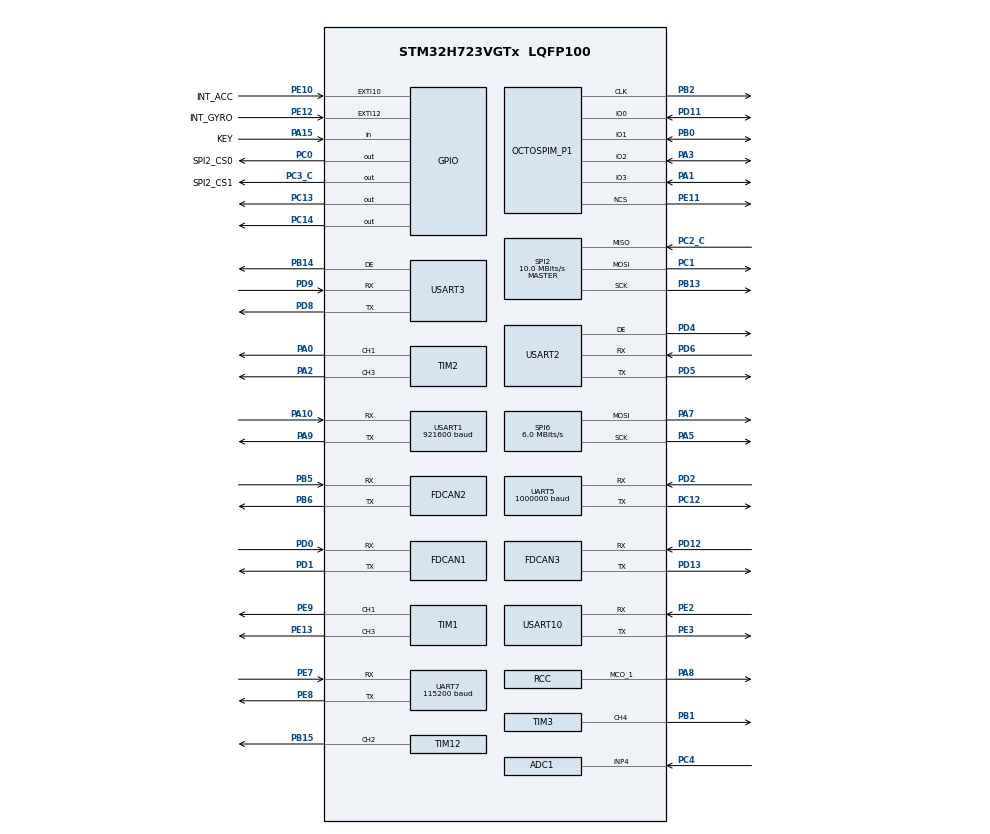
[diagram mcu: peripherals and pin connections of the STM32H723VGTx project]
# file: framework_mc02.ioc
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ADC1.Channel-0\#ChannelRegularConversion=ADC_CHANNEL_4
ADC1.ClockPrescaler=ADC_CLOCK_ASYNC_DIV64
ADC1.ContinuousConvMode=ENABLE
ADC1.ConversionDataManagement=ADC_CONVERSIONDATA_DMA_CIRCULAR
ADC1.EnableAnalogWatchDog1=false
ADC1.NbrOfConversionFlag=1
ADC1.OffsetNumber-0\#ChannelRegularConversion=ADC_OFFSET_NONE
ADC1.OffsetSignedSaturation-0\#ChannelRegularConversion=DISABLE
ADC1.Rank-0\#ChannelRegularConversion=1
ADC1.SamplingTime-0\#ChannelRegularConversion=ADC_SAMPLETIME_32CYCLES_5
ADC1.master=1
Bdma.Request0=SPI6_TX
Bdma.RequestsNb=1
Bdma.SPI6_TX.0.Direction=DMA_MEMORY_TO_PERIPH
Bdma.SPI6_TX.0.EventEnable=DISABLE
Bdma.SPI6_TX.0.Instance=BDMA_Channel0
Bdma.SPI6_TX.0.MemDataAlignment=DMA_MDATAALIGN_BYTE
Bdma.SPI6_TX.0.MemInc=DMA_MINC_ENABLE
Bdma.SPI6_TX.0.Mode=DMA_NORMAL
Bdma.SPI6_TX.0.PeriphDataAlignment=DMA_PDATAALIGN_BYTE
Bdma.SPI6_TX.0.PeriphInc=DMA_PINC_DISABLE
Bdma.SPI6_TX.0.Polarity=HAL_DMAMUX_REQ_GEN_RISING
Bdma.SPI6_TX.0.Priority=DMA_PRIORITY_LOW
Bdma.SPI6_TX.0.RequestNumber=1
Bdma.SPI6_TX.0.SignalID=NONE
Bdma.SPI6_TX.0.SyncEnable=DISABLE
Bdma.SPI6_TX.0.SyncPolarity=HAL_DMAMUX_SYNC_NO_EVENT
Bdma.SPI6_TX.0.SyncRequestNumber=1
Bdma.SPI6_TX.0.SyncSignalID=NONE
CORTEX_M7.AccessPermission-Cortex_Memory_Protection_Unit_Region10_Settings=MPU_REGION_FULL_ACCESS
CORTEX_M7.AccessPermission-Cortex_Memory_Protection_Unit_Region11_Settings=MPU_REGION_FULL_ACCESS
CORTEX_M7.AccessPermission-Cortex_Memory_Protection_Unit_Region12_Settings=MPU_REGION_FULL_ACCESS
CORTEX_M7.AccessPermission-Cortex_Memory_Protection_Unit_Region1_Settings=MPU_REGION_PRIV_RO
CORTEX_M7.AccessPermission-Cortex_Memory_Protection_Unit_Region2_Settings=MPU_REGION_FULL_ACCESS
CORTEX_M7.AccessPermission-Cortex_Memory_Protection_Unit_Region3_Settings=MPU_REGION_FULL_ACCESS
CORTEX_M7.AccessPermission-Cortex_Memory_Protection_Unit_Region4_Settings=MPU_REGION_FULL_ACCESS
CORTEX_M7.AccessPermission-Cortex_Memory_Protection_Unit_Region5_Settings=MPU_REGION_FULL_ACCESS
CORTEX_M7.AccessPermission-Cortex_Memory_Protection_Unit_Region6_Settings=MPU_REGION_FULL_ACCESS
CORTEX_M7.AccessPermission-Cortex_Memory_Protection_Unit_Region7_Settings=MPU_REGION_FULL_ACCESS
CORTEX_M7.AccessPermission-Cortex_Memory_Protection_Unit_Region8_Settings=MPU_REGION_FULL_ACCESS
CORTEX_M7.AccessPermission-Cortex_Memory_Protection_Unit_Region9_Settings=MPU_REGION_FULL_ACCESS
CORTEX_M7.BaseAddress-Cortex_Memory_Protection_Unit_Region10_Settings=0x48020000
CORTEX_M7.BaseAddress-Cortex_Memory_Protection_Unit_Region11_Settings=0x40020000
CORTEX_M7.BaseAddress-Cortex_Memory_Protection_Unit_Region12_Settings=0x40010000
CORTEX_M7.BaseAddress-Cortex_Memory_Protection_Unit_Region2_Settings=0x20000000
CORTEX_M7.BaseAddress-Cortex_Memory_Protection_Unit_Region3_Settings=0x24000000
CORTEX_M7.BaseAddress-Cortex_Memory_Protection_Unit_Region4_Settings=0x30000000
CORTEX_M7.BaseAddress-Cortex_Memory_Protection_Unit_Region5_Settings=0x38000000
CORTEX_M7.BaseAddress-Cortex_Memory_Protection_Unit_Region6_Settings=0x38800000
CORTEX_M7.BaseAddress-Cortex_Memory_Protection_Unit_Region7_Settings=0x58000000
CORTEX_M7.BaseAddress-Cortex_Memory_Protection_Unit_Region8_Settings=0x51000000
CORTEX_M7.BaseAddress-Cortex_Memory_Protection_Unit_Region9_Settings=0x50000000
CORTEX_M7.CPU_DCache=Enabled
CORTEX_M7.CPU_ICache=Enabled
CORTEX_M7.DisableExec-Cortex_Memory_Protection_Unit_Region0_Settings=MPU_INSTRUCTION_ACCESS_DISABLE
CORTEX_M7.Enable-Cortex_Memory_Protection_Unit_Region0_Settings=MPU_REGION_ENABLE
CORTEX_M7.Enable-Cortex_Memory_Protection_Unit_Region10_Settings=MPU_REGION_ENABLE
CORTEX_M7.Enable-Cortex_Memory_Protection_Unit_Region11_Settings=MPU_REGION_ENABLE
CORTEX_M7.Enable-Cortex_Memory_Protection_Unit_Region12_Settings=MPU_REGION_ENABLE
CORTEX_M7.Enable-Cortex_Memory_Protection_Unit_Region1_Settings=MPU_REGION_ENABLE
CORTEX_M7.Enable-Cortex_Memory_Protection_Unit_Region2_Settings=MPU_REGION_ENABLE
CORTEX_M7.Enable-Cortex_Memory_Protection_Unit_Region3_Settings=MPU_REGION_ENABLE
CORTEX_M7.Enable-Cortex_Memory_Protection_Unit_Region4_Settings=MPU_REGION_ENABLE
CORTEX_M7.Enable-Cortex_Memory_Protection_Unit_Region5_Settings=MPU_REGION_ENABLE
CORTEX_M7.Enable-Cortex_Memory_Protection_Unit_Region6_Settings=MPU_REGION_ENABLE
CORTEX_M7.Enable-Cortex_Memory_Protection_Unit_Region7_Settings=MPU_REGION_ENABLE
CORTEX_M7.Enable-Cortex_Memory_Protection_Unit_Region8_Settings=MPU_REGION_ENABLE
CORTEX_M7.Enable-Cortex_Memory_Protection_Unit_Region9_Settings=MPU_REGION_ENABLE
CORTEX_M7.IsBufferable-Cortex_Memory_Protection_Unit_Region1_Settings=MPU_ACCESS_NOT_BUFFERABLE
CORTEX_M7.IsBufferable-Cortex_Memory_Protection_Unit_Region2_Settings=MPU_ACCESS_BUFFERABLE
CORTEX_M7.IsCacheable-Cortex_Memory_Protection_Unit_Region1_Settings=MPU_ACCESS_CACHEABLE
CORTEX_M7.IsCacheable-Cortex_Memory_Protection_Unit_Region2_Settings=MPU_ACCESS_CACHEABLE
CORTEX_M7.IsCacheable-Cortex_Memory_Protection_Unit_Region3_Settings=MPU_ACCESS_CACHEABLE
CORTEX_M7.MPU_Control=MPU_PRIVILEGED_DEFAULT
CORTEX_M7.Size-Cortex_Memory_Protection_Unit_Region10_Settings=MPU_REGION_SIZE_16KB
CORTEX_M7.Size-Cortex_Memory_Protection_Unit_Region11_Settings=MPU_REGION_SIZE_1MB
CORTEX_M7.Size-Cortex_Memory_Protection_Unit_Region12_Settings=MPU_REGION_SIZE_32KB
CORTEX_M7.Size-Cortex_Memory_Protection_Unit_Region1_Settings=MPU_REGION_SIZE_64KB
CORTEX_M7.Size-Cortex_Memory_Protection_Unit_Region2_Settings=MPU_REGION_SIZE_128KB
CORTEX_M7.Size-Cortex_Memory_Protection_Unit_Region3_Settings=MPU_REGION_SIZE_512KB
CORTEX_M7.Size-Cortex_Memory_Protection_Unit_Region4_Settings=MPU_REGION_SIZE_32KB
CORTEX_M7.Size-Cortex_Memory_Protection_Unit_Region5_Settings=MPU_REGION_SIZE_16KB
CORTEX_M7.Size-Cortex_Memory_Protection_Unit_Region6_Settings=MPU_REGION_SIZE_4KB
CORTEX_M7.Size-Cortex_Memory_Protection_Unit_Region7_Settings=MPU_REGION_SIZE_256KB
CORTEX_M7.Size-Cortex_Memory_Protection_Unit_Region8_Settings=MPU_REGION_SIZE_64KB
CORTEX_M7.Size-Cortex_Memory_Protection_Unit_Region9_Settings=MPU_REGION_SIZE_16KB
CORTEX_M7.SubRegionDisable-Cortex_Memory_Protection_Unit_Region10_Settings=0x03
CORTEX_M7.SubRegionDisable-Cortex_Memory_Protection_Unit_Region11_Settings=0x07
CORTEX_M7.SubRegionDisable-Cortex_Memory_Protection_Unit_Region3_Settings=0x07
CORTEX_M7.SubRegionDisable-Cortex_Memory_Protection_Unit_Region7_Settings=0x07
CORTEX_M7.SubRegionDisable-Cortex_Memory_Protection_Unit_Region8_Settings=0x07
CORTEX_M7.TypeExtField-Cortex_Memory_Protection_Unit_Region10_Settings=MPU_TEX_LEVEL1
CORTEX_M7.TypeExtField-Cortex_Memory_Protection_Unit_Region11_Settings=MPU_TEX_LEVEL1
CORTEX_M7.TypeExtField-Cortex_Memory_Protection_Unit_Region12_Settings=MPU_TEX_LEVEL1
CORTEX_M7.TypeExtField-Cortex_Memory_Protection_Unit_Region7_Settings=MPU_TEX_LEVEL1
CORTEX_M7.TypeExtField-Cortex_Memory_Protection_Unit_Region8_Settings=MPU_TEX_LEVEL1
CORTEX_M7.TypeExtField-Cortex_Memory_Protection_Unit_Region9_Settings=MPU_TEX_LEVEL1
CORTEX_M7.default_mode_Activation=0
Dma.ADC1.0.Direction=DMA_PERIPH_TO_MEMORY
Dma.ADC1.0.EventEnable=DISABLE
Dma.ADC1.0.FIFOMode=DMA_FIFOMODE_DISABLE
Dma.ADC1.0.Instance=DMA1_Stream0
Dma.ADC1.0.MemDataAlignment=DMA_MDATAALIGN_HALFWORD
Dma.ADC1.0.MemInc=DMA_MINC_ENABLE
Dma.ADC1.0.Mode=DMA_NORMAL
Dma.ADC1.0.PeriphDataAlignment=DMA_PDATAALIGN_HALFWORD
Dma.ADC1.0.PeriphInc=DMA_PINC_DISABLE
Dma.ADC1.0.Polarity=HAL_DMAMUX_REQ_GEN_RISING
Dma.ADC1.0.Priority=DMA_PRIORITY_LOW
Dma.ADC1.0.RequestNumber=1
Dma.ADC1.0.SignalID=NONE
Dma.ADC1.0.SyncEnable=DISABLE
Dma.ADC1.0.SyncPolarity=HAL_DMAMUX_SYNC_NO_EVENT
Dma.ADC1.0.SyncRequestNumber=1
Dma.ADC1.0.SyncSignalID=NONE
Dma.Request0=ADC1
Dma.Request1=USART1_RX
Dma.Request10=UART7_RX
Dma.Request11=UART7_TX
Dma.Request12=SPI2_TX
Dma.Request13=SPI2_RX
Dma.Request2=USART1_TX
Dma.Request3=USART2_RX
Dma.Request4=USART2_TX
Dma.Request5=USART3_RX
Dma.Request6=USART3_TX
Dma.Request7=USART10_RX
Dma.Request8=USART10_TX
Dma.Request9=UART5_RX
Dma.SPI2_RX.13.Direction=DMA_PERIPH_TO_MEMORY
Dma.SPI2_RX.13.EventEnable=DISABLE
Dma.SPI2_RX.13.FIFOMode=DMA_FIFOMODE_DISABLE
Dma.SPI2_RX.13.Instance=DMA2_Stream5
Dma.SPI2_RX.13.MemDataAlignment=DMA_MDATAALIGN_BYTE
Dma.SPI2_RX.13.MemInc=DMA_MINC_ENABLE
Dma.SPI2_RX.13.Mode=DMA_NORMAL
Dma.SPI2_RX.13.PeriphDataAlignment=DMA_PDATAALIGN_BYTE
Dma.SPI2_RX.13.PeriphInc=DMA_PINC_DISABLE
Dma.SPI2_RX.13.Polarity=HAL_DMAMUX_REQ_GEN_RISING
Dma.SPI2_RX.13.Priority=DMA_PRIORITY_LOW
Dma.SPI2_RX.13.RequestNumber=1
Dma.SPI2_RX.13.SignalID=NONE
Dma.SPI2_RX.13.SyncEnable=DISABLE
Dma.SPI2_RX.13.SyncPolarity=HAL_DMAMUX_SYNC_NO_EVENT
Dma.SPI2_RX.13.SyncRequestNumber=1
Dma.SPI2_RX.13.SyncSignalID=NONE
Dma.SPI2_TX.12.Direction=DMA_MEMORY_TO_PERIPH
Dma.SPI2_TX.12.EventEnable=DISABLE
Dma.SPI2_TX.12.FIFOMode=DMA_FIFOMODE_DISABLE
Dma.SPI2_TX.12.Instance=DMA2_Stream4
Dma.SPI2_TX.12.MemDataAlignment=DMA_MDATAALIGN_BYTE
Dma.SPI2_TX.12.MemInc=DMA_MINC_ENABLE
Dma.SPI2_TX.12.Mode=DMA_NORMAL
Dma.SPI2_TX.12.PeriphDataAlignment=DMA_PDATAALIGN_BYTE
Dma.SPI2_TX.12.PeriphInc=DMA_PINC_DISABLE
Dma.SPI2_TX.12.Polarity=HAL_DMAMUX_REQ_GEN_RISING
Dma.SPI2_TX.12.Priority=DMA_PRIORITY_LOW
Dma.SPI2_TX.12.RequestNumber=1
Dma.SPI2_TX.12.SignalID=NONE
Dma.SPI2_TX.12.SyncEnable=DISABLE
Dma.SPI2_TX.12.SyncPolarity=HAL_DMAMUX_SYNC_NO_EVENT
Dma.SPI2_TX.12.SyncRequestNumber=1
Dma.SPI2_TX.12.SyncSignalID=NONE
Dma.UART5_RX.9.Direction=DMA_PERIPH_TO_MEMORY
Dma.UART5_RX.9.EventEnable=DISABLE
Dma.UART5_RX.9.FIFOMode=DMA_FIFOMODE_DISABLE
Dma.UART5_RX.9.Instance=DMA2_Stream1
Dma.UART5_RX.9.MemDataAlignment=DMA_MDATAALIGN_BYTE
Dma.UART5_RX.9.MemInc=DMA_MINC_ENABLE
Dma.UART5_RX.9.Mode=DMA_NORMAL
Dma.UART5_RX.9.PeriphDataAlignment=DMA_PDATAALIGN_BYTE
Dma.UART5_RX.9.PeriphInc=DMA_PINC_DISABLE
Dma.UART5_RX.9.Polarity=HAL_DMAMUX_REQ_GEN_RISING
Dma.UART5_RX.9.Priority=DMA_PRIORITY_LOW
Dma.UART5_RX.9.RequestNumber=1
Dma.UART5_RX.9.SignalID=NONE
Dma.UART5_RX.9.SyncEnable=DISABLE
Dma.UART5_RX.9.SyncPolarity=HAL_DMAMUX_SYNC_NO_EVENT
Dma.UART5_RX.9.SyncRequestNumber=1
Dma.UART5_RX.9.SyncSignalID=NONE
Dma.UART7_RX.10.Direction=DMA_PERIPH_TO_MEMORY
Dma.UART7_RX.10.EventEnable=DISABLE
Dma.UART7_RX.10.FIFOMode=DMA_FIFOMODE_DISABLE
Dma.UART7_RX.10.Instance=DMA2_Stream2
Dma.UART7_RX.10.MemDataAlignment=DMA_MDATAALIGN_BYTE
Dma.UART7_RX.10.MemInc=DMA_MINC_ENABLE
Dma.UART7_RX.10.Mode=DMA_NORMAL
Dma.UART7_RX.10.PeriphDataAlignment=DMA_PDATAALIGN_BYTE
Dma.UART7_RX.10.PeriphInc=DMA_PINC_DISABLE
Dma.UART7_RX.10.Polarity=HAL_DMAMUX_REQ_GEN_RISING
Dma.UART7_RX.10.Priority=DMA_PRIORITY_LOW
Dma.UART7_RX.10.RequestNumber=1
Dma.UART7_RX.10.SignalID=NONE
Dma.UART7_RX.10.SyncEnable=DISABLE
Dma.UART7_RX.10.SyncPolarity=HAL_DMAMUX_SYNC_NO_EVENT
Dma.UART7_RX.10.SyncRequestNumber=1
Dma.UART7_RX.10.SyncSignalID=NONE
Dma.UART7_TX.11.Direction=DMA_MEMORY_TO_PERIPH
Dma.UART7_TX.11.EventEnable=DISABLE
Dma.UART7_TX.11.FIFOMode=DMA_FIFOMODE_DISABLE
Dma.UART7_TX.11.Instance=DMA2_Stream3
Dma.UART7_TX.11.MemDataAlignment=DMA_MDATAALIGN_BYTE
Dma.UART7_TX.11.MemInc=DMA_MINC_ENABLE
Dma.UART7_TX.11.Mode=DMA_NORMAL
Dma.UART7_TX.11.PeriphDataAlignment=DMA_PDATAALIGN_BYTE
Dma.UART7_TX.11.PeriphInc=DMA_PINC_DISABLE
Dma.UART7_TX.11.Polarity=HAL_DMAMUX_REQ_GEN_RISING
Dma.UART7_TX.11.Priority=DMA_PRIORITY_LOW
Dma.UART7_TX.11.RequestNumber=1
Dma.UART7_TX.11.SignalID=NONE
Dma.UART7_TX.11.SyncEnable=DISABLE
Dma.UART7_TX.11.SyncPolarity=HAL_DMAMUX_SYNC_NO_EVENT
Dma.UART7_TX.11.SyncRequestNumber=1
Dma.UART7_TX.11.SyncSignalID=NONE
Dma.USART10_RX.7.Direction=DMA_PERIPH_TO_MEMORY
Dma.USART10_RX.7.EventEnable=DISABLE
Dma.USART10_RX.7.FIFOMode=DMA_FIFOMODE_DISABLE
Dma.USART10_RX.7.Instance=DMA1_Stream7
Dma.USART10_RX.7.MemDataAlignment=DMA_MDATAALIGN_BYTE
Dma.USART10_RX.7.MemInc=DMA_MINC_ENABLE
Dma.USART10_RX.7.Mode=DMA_NORMAL
Dma.USART10_RX.7.PeriphDataAlignment=DMA_PDATAALIGN_BYTE
Dma.USART10_RX.7.PeriphInc=DMA_PINC_DISABLE
Dma.USART10_RX.7.Polarity=HAL_DMAMUX_REQ_GEN_RISING
Dma.USART10_RX.7.Priority=DMA_PRIORITY_LOW
Dma.USART10_RX.7.RequestNumber=1
Dma.USART10_RX.7.SignalID=NONE
Dma.USART10_RX.7.SyncEnable=DISABLE
Dma.USART10_RX.7.SyncPolarity=HAL_DMAMUX_SYNC_NO_EVENT
Dma.USART10_RX.7.SyncRequestNumber=1
Dma.USART10_RX.7.SyncSignalID=NONE
Dma.USART10_TX.8.Direction=DMA_MEMORY_TO_PERIPH
Dma.USART10_TX.8.EventEnable=DISABLE
Dma.USART10_TX.8.FIFOMode=DMA_FIFOMODE_DISABLE
Dma.USART10_TX.8.Instance=DMA2_Stream0
Dma.USART10_TX.8.MemDataAlignment=DMA_MDATAALIGN_BYTE
Dma.USART10_TX.8.MemInc=DMA_MINC_ENABLE
Dma.USART10_TX.8.Mode=DMA_NORMAL
Dma.USART10_TX.8.PeriphDataAlignment=DMA_PDATAALIGN_BYTE
Dma.USART10_TX.8.PeriphInc=DMA_PINC_DISABLE
Dma.USART10_TX.8.Polarity=HAL_DMAMUX_REQ_GEN_RISING
Dma.USART10_TX.8.Priority=DMA_PRIORITY_LOW
Dma.USART10_TX.8.RequestNumber=1
Dma.USART10_TX.8.SignalID=NONE
Dma.USART10_TX.8.SyncEnable=DISABLE
Dma.USART10_TX.8.SyncPolarity=HAL_DMAMUX_SYNC_NO_EVENT
Dma.USART10_TX.8.SyncRequestNumber=1
Dma.USART10_TX.8.SyncSignalID=NONE
Dma.USART1_RX.1.Direction=DMA_PERIPH_TO_MEMORY
Dma.USART1_RX.1.EventEnable=DISABLE
Dma.USART1_RX.1.FIFOMode=DMA_FIFOMODE_DISABLE
Dma.USART1_RX.1.Instance=DMA1_Stream1
Dma.USART1_RX.1.MemDataAlignment=DMA_MDATAALIGN_BYTE
Dma.USART1_RX.1.MemInc=DMA_MINC_ENABLE
Dma.USART1_RX.1.Mode=DMA_NORMAL
Dma.USART1_RX.1.PeriphDataAlignment=DMA_PDATAALIGN_BYTE
Dma.USART1_RX.1.PeriphInc=DMA_PINC_DISABLE
Dma.USART1_RX.1.Polarity=HAL_DMAMUX_REQ_GEN_RISING
Dma.USART1_RX.1.Priority=DMA_PRIORITY_LOW
Dma.USART1_RX.1.RequestNumber=1
Dma.USART1_RX.1.SignalID=NONE
Dma.USART1_RX.1.SyncEnable=DISABLE
Dma.USART1_RX.1.SyncPolarity=HAL_DMAMUX_SYNC_NO_EVENT
Dma.USART1_RX.1.SyncRequestNumber=1
Dma.USART1_RX.1.SyncSignalID=NONE
Dma.USART1_TX.2.Direction=DMA_MEMORY_TO_PERIPH
Dma.USART1_TX.2.EventEnable=DISABLE
Dma.USART1_TX.2.FIFOMode=DMA_FIFOMODE_DISABLE
Dma.USART1_TX.2.Instance=DMA1_Stream2
Dma.USART1_TX.2.MemDataAlignment=DMA_MDATAALIGN_BYTE
Dma.USART1_TX.2.MemInc=DMA_MINC_ENABLE
Dma.USART1_TX.2.Mode=DMA_NORMAL
Dma.USART1_TX.2.PeriphDataAlignment=DMA_PDATAALIGN_BYTE
Dma.USART1_TX.2.PeriphInc=DMA_PINC_DISABLE
Dma.USART1_TX.2.Polarity=HAL_DMAMUX_REQ_GEN_RISING
Dma.USART1_TX.2.Priority=DMA_PRIORITY_LOW
Dma.USART1_TX.2.RequestNumber=1
Dma.USART1_TX.2.SignalID=NONE
Dma.USART1_TX.2.SyncEnable=DISABLE
Dma.USART1_TX.2.SyncPolarity=HAL_DMAMUX_SYNC_NO_EVENT
Dma.USART1_TX.2.SyncRequestNumber=1
Dma.USART1_TX.2.SyncSignalID=NONE
Dma.USART2_RX.3.Direction=DMA_PERIPH_TO_MEMORY
Dma.USART2_RX.3.EventEnable=DISABLE
Dma.USART2_RX.3.FIFOMode=DMA_FIFOMODE_DISABLE
Dma.USART2_RX.3.Instance=DMA1_Stream3
Dma.USART2_RX.3.MemDataAlignment=DMA_MDATAALIGN_BYTE
Dma.USART2_RX.3.MemInc=DMA_MINC_ENABLE
Dma.USART2_RX.3.Mode=DMA_NORMAL
Dma.USART2_RX.3.PeriphDataAlignment=DMA_PDATAALIGN_BYTE
Dma.USART2_RX.3.PeriphInc=DMA_PINC_DISABLE
Dma.USART2_RX.3.Polarity=HAL_DMAMUX_REQ_GEN_RISING
Dma.USART2_RX.3.Priority=DMA_PRIORITY_LOW
Dma.USART2_RX.3.RequestNumber=1
Dma.USART2_RX.3.SignalID=NONE
Dma.USART2_RX.3.SyncEnable=DISABLE
Dma.USART2_RX.3.SyncPolarity=HAL_DMAMUX_SYNC_NO_EVENT
Dma.USART2_RX.3.SyncRequestNumber=1
Dma.USART2_RX.3.SyncSignalID=NONE
Dma.USART2_TX.4.Direction=DMA_MEMORY_TO_PERIPH
Dma.USART2_TX.4.EventEnable=DISABLE
Dma.USART2_TX.4.FIFOMode=DMA_FIFOMODE_DISABLE
Dma.USART2_TX.4.Instance=DMA1_Stream4
Dma.USART2_TX.4.MemDataAlignment=DMA_MDATAALIGN_BYTE
Dma.USART2_TX.4.MemInc=DMA_MINC_ENABLE
Dma.USART2_TX.4.Mode=DMA_NORMAL
Dma.USART2_TX.4.PeriphDataAlignment=DMA_PDATAALIGN_BYTE
Dma.USART2_TX.4.PeriphInc=DMA_PINC_DISABLE
Dma.USART2_TX.4.Polarity=HAL_DMAMUX_REQ_GEN_RISING
Dma.USART2_TX.4.Priority=DMA_PRIORITY_LOW
Dma.USART2_TX.4.RequestNumber=1
Dma.USART2_TX.4.SignalID=NONE
Dma.USART2_TX.4.SyncEnable=DISABLE
Dma.USART2_TX.4.SyncPolarity=HAL_DMAMUX_SYNC_NO_EVENT
Dma.USART2_TX.4.SyncRequestNumber=1
Dma.USART2_TX.4.SyncSignalID=NONE
Dma.USART3_RX.5.Direction=DMA_PERIPH_TO_MEMORY
Dma.USART3_RX.5.EventEnable=DISABLE
Dma.USART3_RX.5.FIFOMode=DMA_FIFOMODE_DISABLE
Dma.USART3_RX.5.Instance=DMA1_Stream5
Dma.USART3_RX.5.MemDataAlignment=DMA_MDATAALIGN_BYTE
Dma.USART3_RX.5.MemInc=DMA_MINC_ENABLE
Dma.USART3_RX.5.Mode=DMA_NORMAL
Dma.USART3_RX.5.PeriphDataAlignment=DMA_PDATAALIGN_BYTE
Dma.USART3_RX.5.PeriphInc=DMA_PINC_DISABLE
Dma.USART3_RX.5.Polarity=HAL_DMAMUX_REQ_GEN_RISING
Dma.USART3_RX.5.Priority=DMA_PRIORITY_LOW
Dma.USART3_RX.5.RequestNumber=1
Dma.USART3_RX.5.SignalID=NONE
Dma.USART3_RX.5.SyncEnable=DISABLE
Dma.USART3_RX.5.SyncPolarity=HAL_DMAMUX_SYNC_NO_EVENT
Dma.USART3_RX.5.SyncRequestNumber=1
Dma.USART3_RX.5.SyncSignalID=NONE
Dma.USART3_TX.6.Direction=DMA_MEMORY_TO_PERIPH
Dma.USART3_TX.6.EventEnable=DISABLE
Dma.USART3_TX.6.FIFOMode=DMA_FIFOMODE_DISABLE
Dma.USART3_TX.6.Instance=DMA1_Stream6
Dma.USART3_TX.6.MemDataAlignment=DMA_MDATAALIGN_BYTE
Dma.USART3_TX.6.MemInc=DMA_MINC_ENABLE
Dma.USART3_TX.6.Mode=DMA_NORMAL
Dma.USART3_TX.6.PeriphDataAlignment=DMA_PDATAALIGN_BYTE
Dma.USART3_TX.6.PeriphInc=DMA_PINC_DISABLE
Dma.USART3_TX.6.Polarity=HAL_DMAMUX_REQ_GEN_RISING
Dma.USART3_TX.6.Priority=DMA_PRIORITY_LOW
Dma.USART3_TX.6.RequestNumber=1
Dma.USART3_TX.6.SignalID=NONE
Dma.USART3_TX.6.SyncEnable=DISABLE
Dma.USART3_TX.6.SyncPolarity=HAL_DMAMUX_SYNC_NO_EVENT
Dma.USART3_TX.6.SyncRequestNumber=1
Dma.USART3_TX.6.SyncSignalID=NONE
FDCAN1.CalculateBaudRateNominal=1000000
FDCAN1.CalculateTimeBitNominal=1000
FDCAN1.CalculateTimeQuantumNominal=25.0
FDCAN1.DataPrescaler=1
FDCAN1.DataSyncJumpWidth=2
FDCAN1.DataTimeSeg1=10
FDCAN1.DataTimeSeg2=5
FDCAN1.ExtFiltersNbr=1
FDCAN1.FrameFormat=FDCAN_FRAME_FD_BRS
FDCAN1.NominalPrescaler=2
FDCAN1.NominalSyncJumpWidth=2
FDCAN1.NominalTimeSeg1=29
FDCAN1.NominalTimeSeg2=10
FDCAN1.ProtocolException=ENABLE
FDCAN1.RxFifo0ElmtSize=FDCAN_DATA_BYTES_64
FDCAN1.RxFifo0ElmtsNbr=8
FDCAN1.RxFifo1ElmtsNbr=0
FDCAN1.StdFiltersNbr=1
FDCAN1.TxElmtSize=FDCAN_DATA_BYTES_64
FDCAN1.TxFifoQueueElmtsNbr=32
FDCAN2.CalculateBaudRateNominal=1000000
FDCAN2.CalculateTimeBitNominal=1000
FDCAN2.CalculateTimeQuantumNominal=25.0
FDCAN2.DataPrescaler=1
FDCAN2.DataSyncJumpWidth=2
FDCAN2.DataTimeSeg1=10
FDCAN2.DataTimeSeg2=5
FDCAN2.ExtFiltersNbr=1
FDCAN2.FrameFormat=FDCAN_FRAME_FD_BRS
FDCAN2.MessageRAMOffset=(768 - 1)
FDCAN2.NominalPrescaler=2
FDCAN2.NominalSyncJumpWidth=2
FDCAN2.NominalTimeSeg1=29
FDCAN2.NominalTimeSeg2=10
FDCAN2.ProtocolException=ENABLE
FDCAN2.RxFifo0ElmtSize=FDCAN_DATA_BYTES_8
FDCAN2.RxFifo0ElmtsNbr=0
FDCAN2.RxFifo1ElmtSize=FDCAN_DATA_BYTES_64
FDCAN2.RxFifo1ElmtsNbr=8
FDCAN2.StdFiltersNbr=1
FDCAN2.TxElmtSize=FDCAN_DATA_BYTES_64
FDCAN2.TxFifoQueueElmtsNbr=32
FDCAN3.CalculateBaudRateNominal=1000000
FDCAN3.CalculateTimeBitNominal=1000
FDCAN3.CalculateTimeQuantumNominal=25.0
FDCAN3.DataPrescaler=1
FDCAN3.DataSyncJumpWidth=2
FDCAN3.DataTimeSeg1=10
FDCAN3.DataTimeSeg2=5
FDCAN3.ExtFiltersNbr=1
FDCAN3.FrameFormat=FDCAN_FRAME_FD_BRS
FDCAN3.MessageRAMOffset=(1536 - 1)
FDCAN3.NominalPrescaler=2
FDCAN3.NominalSyncJumpWidth=2
FDCAN3.NominalTimeSeg1=29
FDCAN3.NominalTimeSeg2=10
FDCAN3.ProtocolException=ENABLE
FDCAN3.RxFifo1ElmtSize=FDCAN_DATA_BYTES_64
FDCAN3.RxFifo1ElmtsNbr=8
FDCAN3.StdFiltersNbr=1
FDCAN3.TxElmtSize=FDCAN_DATA_BYTES_64
FDCAN3.TxFifoQueueElmtsNbr=32
FREERTOS.INCLUDE_vTaskCleanUpResources=1
FREERTOS.INCLUDE_vTaskDelayUntil=0
FREERTOS.INCLUDE_xTaskGetCurrentTaskHandle=1
FREERTOS.Tasks01=defaultTask,0,1024,StartDefaultTask,As weak,NULL,Dynamic,NULL,NULL
FREERTOS.configCHECK_FOR_STACK_OVERFLOW=2
FREERTOS.configENABLE_BACKWARD_COMPATIBILITY=0
FREERTOS.configENABLE_FPU=1
FREERTOS.configGENERATE_RUN_TIME_STATS=1
FREERTOS.configRECORD_STACK_HIGH_ADDRESS=1
FREERTOS.configTOTAL_HEAP_SIZE=0x8000
FREERTOS.configUSE_COUNTING_SEMAPHORES=1
FREERTOS.configUSE_NEWLIB_REENTRANT=1
FREERTOS.configUSE_POSIX_ERRNO=1
FREERTOS.configUSE_TRACE_FACILITY=1
IWDG1.Prescaler=IWDG_PRESCALER_64
Mcu.Family=STM32H7
Mcu.Name=STM32H723VGTx
Mcu.Package=LQFP100
Mdma.MDMA_Channel0.OCTOSPI1_FIFO_TH.0.BlockCount=0
Mdma.MDMA_Channel0.OCTOSPI1_FIFO_TH.0.BlockDataLength=0
Mdma.MDMA_Channel0.OCTOSPI1_FIFO_TH.0.BufferTransferLength=1
Mdma.MDMA_Channel0.OCTOSPI1_FIFO_TH.0.CircularMode=MDMA_LINEAR_LIST
Mdma.MDMA_Channel0.OCTOSPI1_FIFO_TH.0.DataAlignment=MDMA_DATAALIGN_PACKENABLE
Mdma.MDMA_Channel0.OCTOSPI1_FIFO_TH.0.DestBlockAddressOffset=0
Mdma.MDMA_Channel0.OCTOSPI1_FIFO_TH.0.DestBurst=MDMA_DEST_BURST_SINGLE
Mdma.MDMA_Channel0.OCTOSPI1_FIFO_TH.0.DestDataSize=MDMA_DEST_DATASIZE_BYTE
Mdma.MDMA_Channel0.OCTOSPI1_FIFO_TH.0.DestinationInc=MDMA_DEST_INC_BYTE
Mdma.MDMA_Channel0.OCTOSPI1_FIFO_TH.0.DstAddress=0
Mdma.MDMA_Channel0.OCTOSPI1_FIFO_TH.0.Endianness=MDMA_LITTLE_ENDIANNESS_PRESERVE
Mdma.MDMA_Channel0.OCTOSPI1_FIFO_TH.0.Instance=MDMA_Channel0
Mdma.MDMA_Channel0.OCTOSPI1_FIFO_TH.0.MaskAddress=0
Mdma.MDMA_Channel0.OCTOSPI1_FIFO_TH.0.MaskData=0
Mdma.MDMA_Channel0.OCTOSPI1_FIFO_TH.0.Priority=MDMA_PRIORITY_LOW
Mdma.MDMA_Channel0.OCTOSPI1_FIFO_TH.0.Rank=First
Mdma.MDMA_Channel0.OCTOSPI1_FIFO_TH.0.SourceBlockAddressOffset=0
Mdma.MDMA_Channel0.OCTOSPI1_FIFO_TH.0.SourceBurst=MDMA_SOURCE_BURST_SINGLE
Mdma.MDMA_Channel0.OCTOSPI1_FIFO_TH.0.SourceDataSize=MDMA_SRC_DATASIZE_BYTE
Mdma.MDMA_Channel0.OCTOSPI1_FIFO_TH.0.SourceInc=MDMA_SRC_INC_BYTE
Mdma.MDMA_Channel0.OCTOSPI1_FIFO_TH.0.SrcAddress=0
Mdma.MDMA_Channel0.OCTOSPI1_FIFO_TH.0.TransferTriggerMode=MDMA_BUFFER_TRANSFER
Mdma.MDMA_Channel0.Request0=OCTOSPI1_FIFO_TH
Mdma.MDMA_Channel0.RequestsNb=1
Mdma.RequestSet0=MDMA_Channel0
Mdma.RequestSetsNb=1
NVIC.ADC_IRQn=true\:5\:0\:false\:false\:true\:true\:true\:true\:true
NVIC.BDMA_Channel0_IRQn=true\:5\:0\:false\:false\:true\:true\:false\:true\:true
NVIC.DMA1_Stream0_IRQn=true\:5\:0\:false\:false\:true\:true\:false\:true\:true
NVIC.DMA1_Stream1_IRQn=true\:5\:0\:false\:false\:true\:true\:false\:true\:true
NVIC.DMA1_Stream2_IRQn=true\:5\:0\:false\:false\:true\:true\:false\:true\:true
NVIC.DMA1_Stream3_IRQn=true\:5\:0\:false\:false\:true\:true\:false\:true\:true
NVIC.DMA1_Stream4_IRQn=true\:5\:0\:false\:false\:true\:true\:false\:true\:true
NVIC.DMA1_Stream5_IRQn=true\:5\:0\:false\:false\:true\:true\:false\:true\:true
NVIC.DMA1_Stream6_IRQn=true\:5\:0\:false\:false\:true\:true\:false\:true\:true
NVIC.DMA1_Stream7_IRQn=true\:5\:0\:false\:false\:true\:true\:false\:true\:true
NVIC.DMA2_Stream0_IRQn=true\:5\:0\:false\:false\:true\:true\:false\:true\:true
NVIC.DMA2_Stream1_IRQn=true\:5\:0\:false\:false\:true\:true\:false\:true\:true
NVIC.DMA2_Stream2_IRQn=true\:5\:0\:false\:false\:true\:true\:false\:true\:true
NVIC.DMA2_Stream3_IRQn=true\:5\:0\:false\:false\:true\:true\:false\:true\:true
NVIC.DMA2_Stream4_IRQn=true\:5\:0\:false\:false\:true\:true\:false\:true\:true
NVIC.DMA2_Stream5_IRQn=true\:5\:0\:false\:false\:true\:true\:false\:true\:true
NVIC.EXTI15_10_IRQn=true\:5\:0\:false\:false\:true\:true\:true\:true\:true
NVIC.FDCAN1_IT0_IRQn=true\:5\:0\:false\:false\:true\:true\:true\:true\:true
NVIC.FDCAN1_IT1_IRQn=true\:5\:0\:false\:false\:true\:true\:true\:true\:true
NVIC.FDCAN2_IT0_IRQn=true\:5\:0\:false\:false\:true\:true\:true\:true\:true
NVIC.FDCAN2_IT1_IRQn=true\:5\:0\:false\:false\:true\:true\:true\:true\:true
NVIC.FDCAN3_IT0_IRQn=true\:5\:0\:false\:false\:true\:true\:true\:true\:true
NVIC.FDCAN3_IT1_IRQn=true\:5\:0\:false\:false\:true\:true\:true\:true\:true
NVIC.MDMA_IRQn=true\:5\:0\:false\:false\:true\:true\:false\:true\:true
NVIC.OCTOSPI1_IRQn=true\:5\:0\:false\:false\:true\:true\:true\:true\:true
NVIC.PriorityGroup=NVIC_PRIORITYGROUP_4
NVIC.SPI2_IRQn=true\:5\:0\:false\:false\:true\:true\:false\:true\:true
NVIC.SPI6_IRQn=true\:5\:0\:false\:false\:true\:true\:false\:true\:true
NVIC.TIM17_IRQn=true\:15\:0\:false\:false\:true\:false\:false\:true\:true
NVIC.TIM5_IRQn=true\:5\:0\:false\:false\:true\:true\:true\:true\:true
NVIC.TimeBase=TIM17_IRQn
NVIC.TimeBaseIP=TIM17
NVIC.UART5_IRQn=true\:5\:0\:false\:false\:true\:true\:true\:true\:true
NVIC.UART7_IRQn=true\:5\:0\:false\:false\:true\:true\:true\:true\:true
NVIC.USART10_IRQn=true\:5\:0\:false\:false\:true\:true\:true\:true\:true
NVIC.USART1_IRQn=true\:5\:0\:false\:false\:true\:true\:true\:true\:true
NVIC.USART2_IRQn=true\:5\:0\:false\:false\:true\:true\:true\:true\:true
NVIC.USART3_IRQn=true\:5\:0\:false\:false\:true\:true\:true\:true\:true
OCTOSPI1.ClockMode=HAL_OSPI_CLOCK_MODE_3
OCTOSPI1.ClockPrescaler=3
OCTOSPI1.FifoThreshold=8
OCTOSPI1.SampleShifting=HAL_OSPI_SAMPLE_SHIFTING_HALFCYCLE
PA0.Signal=S_TIM2_CH1_ETR
PA1.Mode=OCTOSPI1_IOL_Port1L
PA1.Signal=OCTOSPIM_P1_IO3
PA10.Mode=Asynchronous
PA10.Signal=USART1_RX
PA13(JTMS/SWDIO).Mode=Serial_Wire
PA13(JTMS/SWDIO).Signal=DEBUG_JTMS-SWDIO
PA14(JTCK/SWCLK).Mode=Serial_Wire
PA14(JTCK/SWCLK).Signal=DEBUG_JTCK-SWCLK
PA15(JTDI).GPIO_Label=KEY
PA15(JTDI).Signal=GPIO_Input
PA2.Signal=S_TIM2_CH3
PA3.Mode=OCTOSPI1_IOL_Port1L
PA3.Signal=OCTOSPIM_P1_IO2
PA5.GPIO_Speed=GPIO_SPEED_FREQ_VERY_HIGH
PA5.Mode=TX_Only_Simplex_Unidirect_Master
PA5.Signal=SPI6_SCK
PA7.GPIO_Speed=GPIO_SPEED_FREQ_VERY_HIGH
PA7.Mode=TX_Only_Simplex_Unidirect_Master
PA7.Signal=SPI6_MOSI
PA8.Mode=Clock-out-1
PA8.Signal=RCC_MCO_1
PA9.Mode=Asynchronous
PA9.Signal=USART1_TX
PB0.Mode=OCTOSPI1_IOL_Port1L
PB0.Signal=OCTOSPIM_P1_IO1
PB1.Signal=S_TIM3_CH4
PB13.GPIO_Speed=GPIO_SPEED_FREQ_VERY_HIGH
PB13.Mode=Full_Duplex_Master
PB13.Signal=SPI2_SCK
PB14.Mode=Hardware Flow Control (RS485)
PB14.Signal=USART3_DE
PB15.Signal=S_TIM12_CH2
PB2.Mode=O1_P1_CLK
PB2.Signal=OCTOSPIM_P1_CLK
PB5.GPIO_Speed=GPIO_SPEED_FREQ_VERY_HIGH
PB5.Mode=FDCAN_Activate
PB5.Signal=FDCAN2_RX
PB6.GPIO_FM6=SYSCFG_PMCR_I2C_PB6_FMP
PB6.GPIO_Speed=GPIO_SPEED_FREQ_VERY_HIGH
PB6.Mode=FDCAN_Activate
PB6.Signal=FDCAN2_TX
PC0.GPIO_Label=SPI2_CS0
PC0.GPIO_Speed=GPIO_SPEED_FREQ_VERY_HIGH
PC0.PinState=GPIO_PIN_SET
PC0.Signal=GPIO_Output
PC1.GPIO_Speed=GPIO_SPEED_FREQ_VERY_HIGH
PC1.Mode=Full_Duplex_Master
PC1.Signal=SPI2_MOSI
PC12.Mode=Asynchronous
PC12.Signal=UART5_TX
PC13.Signal=GPIO_Output
PC14-OSC32_IN.Signal=GPIO_Output
PC2_C.GPIO_Speed=GPIO_SPEED_FREQ_VERY_HIGH
PC2_C.Mode=Full_Duplex_Master
PC2_C.Signal=SPI2_MISO
PC3_C.GPIO_Label=SPI2_CS1
PC3_C.GPIO_Speed=GPIO_SPEED_FREQ_VERY_HIGH
PC3_C.PinState=GPIO_PIN_SET
PC3_C.Signal=GPIO_Output
PC4.Signal=ADCx_INP4
PD0.GPIO_Speed=GPIO_SPEED_FREQ_VERY_HIGH
PD0.Mode=FDCAN_Activate
PD0.Signal=FDCAN1_RX
PD1.GPIO_Speed=GPIO_SPEED_FREQ_VERY_HIGH
PD1.Mode=FDCAN_Activate
PD1.Signal=FDCAN1_TX
PD11.Mode=OCTOSPI1_IOL_Port1L
PD11.Signal=OCTOSPIM_P1_IO0
PD12.GPIO_Speed=GPIO_SPEED_FREQ_VERY_HIGH
PD12.Mode=FDCAN_Activate
PD12.Signal=FDCAN3_RX
PD13.GPIO_Speed=GPIO_SPEED_FREQ_VERY_HIGH
PD13.Mode=FDCAN_Activate
PD13.Signal=FDCAN3_TX
PD2.Mode=Asynchronous
PD2.Signal=UART5_RX
PD4.Mode=Hardware Flow Control (RS485)
PD4.Signal=USART2_DE
PD5.Mode=Asynchronous
PD5.Signal=USART2_TX
PD6.Mode=Asynchronous
PD6.Signal=USART2_RX
PD8.Mode=Asynchronous
PD8.Signal=USART3_TX
PD9.Mode=Asynchronous
PD9.Signal=USART3_RX
PE10.GPIO_Label=INT_ACC
PE10.GPIO_ModeDefaultEXTI=GPIO_MODE_IT_FALLING
PE10.Signal=GPXTI10
PE11.Mode=OCTOSPI1_Port1_NCS
PE11.Signal=OCTOSPIM_P1_NCS
PE12.GPIO_Label=INT_GYRO
PE12.GPIO_ModeDefaultEXTI=GPIO_MODE_IT_FALLING
PE12.Signal=GPXTI12
PE13.Signal=S_TIM1_CH3
PE2.Mode=Asynchronous
PE2.Signal=USART10_RX
PE3.Mode=Asynchronous
PE3.Signal=USART10_TX
PE7.Mode=Asynchronous
PE7.Signal=UART7_RX
PE8.Mode=Asynchronous
PE8.Signal=UART7_TX
PE9.Signal=S_TIM1_CH1
PH0-OSC_IN.Mode=HSE-External-Oscillator
PH0-OSC_IN.Signal=RCC_OSC_IN
PH1-OSC_OUT.Mode=HSE-External-Oscillator
PH1-OSC_OUT.Signal=RCC_OSC_OUT
ProjectManager.HeapSize=0x0
ProjectManager.StackSize=0x6000
ProjectManager.TargetToolchain=CMake
RCC.ADCFreq_Value=96000000
RCC.APB1Freq_Value=120000000
RCC.APB2Freq_Value=120000000
RCC.APB3Freq_Value=120000000
RCC.APB4Freq_Value=120000000
RCC.CKPERSourceSelection=RCC_CLKPSOURCE_HSE
RCC.CortexFreq_Value=480000000
RCC.D1PPRE=RCC_APB3_DIV2
RCC.D2PPRE1=RCC_APB1_DIV2
RCC.D2PPRE2=RCC_APB2_DIV2
RCC.D3PPRE=RCC_APB4_DIV2
RCC.DIVM1=2
RCC.DIVM2=2
RCC.DIVN1=40
RCC.DIVN2=16
RCC.DIVP1=1
RCC.DIVQ1=6
RCC.EnbaleCSS=true
RCC.HCLKFreq_Value=240000000
RCC.HPRE=RCC_HCLK_DIV2
RCC.HSE_VALUE=24000000
RCC.PLL1_VCI_Range-AdvancedSettings=RCC_PLL1VCIRANGE_0
RCC.PLL1_VCO_SEL-AdvancedSettings=RCC_PLL1VCOMEDIUM
RCC.PLL2FRACN=0
RCC.PLL2_VCI_Range-AdvancedSettings=RCC_PLL2VCIRANGE_0
RCC.PLL2_VCO_SEL-AdvancedSettings=RCC_PLL2VCOMEDIUM
RCC.PLL3FRACN=0
RCC.PLL3_VCO_SEL-AdvancedSettings=RCC_PLL3VCOWIDE
RCC.PLLFRACN=0
RCC.PLLSourceVirtual=RCC_PLLSOURCE_HSE
RCC.SPI6CLockSelection=RCC_SPI6CLKSOURCE_HSE
RCC.SYSCLKFreq_VALUE=480000000
RCC.SYSCLKSource=RCC_SYSCLKSOURCE_PLLCLK
RCC.Tim2Mul=1
RCC.USBFreq_Value=80000000
SH.ADCx_INP4.0=ADC1_INP4,IN4-Single-Ended
SH.S_TIM12_CH2.0=TIM12_CH2,PWM Generation2 CH2
SH.S_TIM1_CH1.0=TIM1_CH1,PWM Generation1 CH1
SH.S_TIM1_CH3.0=TIM1_CH3,Output Compare3 CH3
SH.S_TIM2_CH1_ETR.0=TIM2_CH1,PWM Generation1 CH1
SH.S_TIM2_CH3.0=TIM2_CH3,PWM Generation3 CH3
SH.S_TIM3_CH4.0=TIM3_CH4,PWM Generation4 CH4
SPI2.BaudRatePrescaler=SPI_BAUDRATEPRESCALER_8
SPI2.CLKPhase=SPI_PHASE_2EDGE
SPI2.CLKPolarity=SPI_POLARITY_HIGH
SPI2.CalculateBaudRate=10.0 MBits/s
SPI2.DataSize=SPI_DATASIZE_8BIT
SPI2.Direction=SPI_DIRECTION_2LINES
SPI2.Mode=SPI_MODE_MASTER
SPI2.VirtualType=VM_MASTER
SPI6.BaudRatePrescaler=SPI_BAUDRATEPRESCALER_4
SPI6.CLKPhase=SPI_PHASE_2EDGE
SPI6.CalculateBaudRate=6.0 MBits/s
SPI6.DataSize=SPI_DATASIZE_8BIT
SPI6.Direction=SPI_DIRECTION_2LINES_TXONLY
SPI6.FifoThreshold=SPI_FIFO_THRESHOLD_01DATA
SPI6.MasterKeepIOState=SPI_MASTER_KEEP_IO_STATE_DISABLE
SPI6.Mode=SPI_MODE_MASTER
SPI6.NSSPMode=SPI_NSS_PULSE_DISABLE
SPI6.VirtualType=VM_MASTER
TIM1.Channel-Output\ Compare3\ CH3=TIM_CHANNEL_3
TIM1.Channel-PWM\ Generation1\ CH1=TIM_CHANNEL_1
TIM12.Channel-PWM\ Generation2\ CH2=TIM_CHANNEL_2
TIM2.Channel-PWM\ Generation1\ CH1=TIM_CHANNEL_1
TIM2.Channel-PWM\ Generation3\ CH3=TIM_CHANNEL_3
TIM3.Channel-PWM\ Generation4\ CH4=TIM_CHANNEL_4
UART5.BaudRate=1000000
UART5.Mode=MODE_RX
UART5.Parity=PARITY_EVEN
UART5.WordLength=WORDLENGTH_9B
UART7.BaudRate=115200
UART7.StopBits=UART_STOPBITS_1
USART1.BaudRate=921600
USART1.VirtualMode-Asynchronous=VM_ASYNC
USART10.VirtualMode=VM_ASYNC
USART2.VirtualMode-Asynchronous=VM_ASYNC
USART2.VirtualMode-Hardware\ Flow\ Control\ (RS485)=VM_ASYNC
USART3.VirtualMode-Asynchronous=VM_ASYNC
USART3.VirtualMode-Hardware\ Flow\ Control\ (RS485)=VM_ASYNC
VP_FREERTOS_VS_CMSIS_V1.Mode=CMSIS_V1
VP_IWDG1_VS_IWDG.Mode=IWDG_Activate
VP_MEMORYMAP_VS_MEMORYMAP.Mode=CurAppReg
VP_OCTOSPI1_VS_quad.Mode=quad_mode
VP_RNG_VS_RNG.Mode=RNG_Activate
VP_SYS_VS_tim17.Mode=TIM17
VP_TIM12_VS_ClockSourceINT.Mode=Internal
VP_TIM1_VS_ClockSourceINT.Mode=Internal
VP_TIM2_VS_ClockSourceINT.Mode=Internal
VP_TIM3_VS_ClockSourceINT.Mode=Internal
VP_TIM5_VS_ClockSourceINT.Mode=Internal
board=custom

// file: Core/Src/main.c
/* USER CODE BEGIN Header */
/**
  ******************************************************************************
  * @file           : main.c
  * @brief          : Main program body
  ******************************************************************************
  * @attention
  *
  * Copyright (c) 2025 STMicroelectronics.
  * All rights reserved.
  *
  * This software is licensed under terms that can be found in the LICENSE file
  * in the root directory of this software component.
  * If no LICENSE file comes with this software, it is provided AS-IS.
  *
  ******************************************************************************
  */
/* USER CODE END Header */
#include "main.h"
#include "cmsis_os.h"
#include "adc.h"
#include "bdma.h"
#include "dma.h"
#include "fdcan.h"
#include "iwdg.h"
#include "mdma.h"
#include "octospi.h"
#include "rng.h"
#include "spi.h"
#include "tim.h"
#include "usart.h"
#include "gpio.h"

void SystemClock_Config(void);
static void MPU_Config(void);
void MX_FREERTOS_Init(void);

int main(void)
{

  /* MPU Configuration--------------------------------------------------------*/
  MPU_Config();

  /* Enable the CPU Cache */

  /* Enable I-Cache---------------------------------------------------------*/
  SCB_EnableICache();

  /* Enable D-Cache---------------------------------------------------------*/
  SCB_EnableDCache();

  /* MCU Configuration--------------------------------------------------------*/

  /* Reset of all peripherals, Initializes the Flash interface and the Systick. */
  HAL_Init();

  /* Configure the system clock */
  SystemClock_Config();

  /* Initialize all configured peripherals */
  MX_GPIO_Init();
  MX_DMA_Init();
  MX_BDMA_Init();
  MX_MDMA_Init();
  MX_ADC1_Init();
  MX_FDCAN1_Init();
  MX_FDCAN2_Init();
  MX_FDCAN3_Init();
  MX_SPI2_Init();
  MX_SPI6_Init();
  MX_TIM1_Init();
  MX_TIM2_Init();
  MX_TIM3_Init();
  MX_TIM12_Init();
  MX_UART5_Init();
  MX_UART7_Init();
  MX_USART1_UART_Init();
  MX_USART2_UART_Init();
  MX_USART3_UART_Init();
  MX_RNG_Init();
  MX_IWDG1_Init();
  MX_TIM5_Init();
  MX_USART10_UART_Init();
  MX_OCTOSPI1_Init();

  /* Call init function for freertos objects (in cmsis_os2.c) */
  MX_FREERTOS_Init();

  /* Start scheduler */
  osKernelStart();

  /* We should never get here as control is now taken by the scheduler */

  /* Infinite loop */
  while (1)
  {

  }
}

void SystemClock_Config(void)
{
  RCC_OscInitTypeDef RCC_OscInitStruct = {0};
  RCC_ClkInitTypeDef RCC_ClkInitStruct = {0};

  /** Supply configuration update enable
  */
  HAL_PWREx_ConfigSupply(PWR_LDO_SUPPLY);

  /** Configure the main internal regulator output voltage
  */
  __HAL_PWR_VOLTAGESCALING_CONFIG(PWR_REGULATOR_VOLTAGE_SCALE0);

  while(!__HAL_PWR_GET_FLAG(PWR_FLAG_VOSRDY)) {}

  /** Initializes the RCC Oscillators according to the specified parameters
  * in the RCC_OscInitTypeDef structure.
  */
  RCC_OscInitStruct.OscillatorType = RCC_OSCILLATORTYPE_HSI48|RCC_OSCILLATORTYPE_HSI
                              |RCC_OSCILLATORTYPE_LSI|RCC_OSCILLATORTYPE_HSE;
  RCC_OscInitStruct.HSEState = RCC_HSE_ON;
  RCC_OscInitStruct.HSIState = RCC_HSI_DIV1;
  RCC_OscInitStruct.HSICalibrationValue = 64;
  RCC_OscInitStruct.LSIState = RCC_LSI_ON;
  RCC_OscInitStruct.HSI48State = RCC_HSI48_ON;
  RCC_OscInitStruct.PLL.PLLState = RCC_PLL_ON;
  RCC_OscInitStruct.PLL.PLLSource = RCC_PLLSOURCE_HSE;
  RCC_OscInitStruct.PLL.PLLM = 2;
  RCC_OscInitStruct.PLL.PLLN = 40;
  RCC_OscInitStruct.PLL.PLLP = 1;
  RCC_OscInitStruct.PLL.PLLQ = 6;
  RCC_OscInitStruct.PLL.PLLR = 2;
  RCC_OscInitStruct.PLL.PLLRGE = RCC_PLL1VCIRANGE_3;
  RCC_OscInitStruct.PLL.PLLVCOSEL = RCC_PLL1VCOWIDE;
  RCC_OscInitStruct.PLL.PLLFRACN = 0;
  if (HAL_RCC_OscConfig(&RCC_OscInitStruct) != HAL_OK)
  {
    Error_Handler();
  }

  /** Initializes the CPU, AHB and APB buses clocks
  */
  RCC_ClkInitStruct.ClockType = RCC_CLOCKTYPE_HCLK|RCC_CLOCKTYPE_SYSCLK
                              |RCC_CLOCKTYPE_PCLK1|RCC_CLOCKTYPE_PCLK2
                              |RCC_CLOCKTYPE_D3PCLK1|RCC_CLOCKTYPE_D1PCLK1;
  RCC_ClkInitStruct.SYSCLKSource = RCC_SYSCLKSOURCE_PLLCLK;
  RCC_ClkInitStruct.SYSCLKDivider = RCC_SYSCLK_DIV1;
  RCC_ClkInitStruct.AHBCLKDivider = RCC_HCLK_DIV2;
  RCC_ClkInitStruct.APB3CLKDivider = RCC_APB3_DIV2;
  RCC_ClkInitStruct.APB1CLKDivider = RCC_APB1_DIV2;
  RCC_ClkInitStruct.APB2CLKDivider = RCC_APB2_DIV2;
  RCC_ClkInitStruct.APB4CLKDivider = RCC_APB4_DIV2;

  if (HAL_RCC_ClockConfig(&RCC_ClkInitStruct, FLASH_LATENCY_3) != HAL_OK)
  {
    Error_Handler();
  }
  HAL_RCC_MCOConfig(RCC_MCO1, RCC_MCO1SOURCE_HSI, RCC_MCODIV_1);

  /** Enables the Clock Security System
  */
  HAL_RCC_EnableCSS();
}

 /* MPU Configuration */

void MPU_Config(void)
{
  MPU_Region_InitTypeDef MPU_InitStruct = {0};

  /* Disables the MPU */
  HAL_MPU_Disable();

  /** Initializes and configures the Region and the memory to be protected
  */
  MPU_InitStruct.Enable = MPU_REGION_ENABLE;
  MPU_InitStruct.Number = MPU_REGION_NUMBER0;
  MPU_InitStruct.BaseAddress = 0x0;
  MPU_InitStruct.Size = MPU_REGION_SIZE_32B;
  MPU_InitStruct.SubRegionDisable = 0x0;
  MPU_InitStruct.TypeExtField = MPU_TEX_LEVEL0;
  MPU_InitStruct.AccessPermission = MPU_REGION_NO_ACCESS;
  MPU_InitStruct.DisableExec = MPU_INSTRUCTION_ACCESS_DISABLE;
  MPU_InitStruct.IsShareable = MPU_ACCESS_NOT_SHAREABLE;
  MPU_InitStruct.IsCacheable = MPU_ACCESS_NOT_CACHEABLE;
  MPU_InitStruct.IsBufferable = MPU_ACCESS_NOT_BUFFERABLE;

  HAL_MPU_ConfigRegion(&MPU_InitStruct);

  /** Initializes and configures the Region and the memory to be protected
  */
  MPU_InitStruct.Number = MPU_REGION_NUMBER1;
  MPU_InitStruct.Size = MPU_REGION_SIZE_64KB;
  MPU_InitStruct.AccessPermission = MPU_REGION_PRIV_RO;
  MPU_InitStruct.DisableExec = MPU_INSTRUCTION_ACCESS_ENABLE;
  MPU_InitStruct.IsCacheable = MPU_ACCESS_CACHEABLE;

  HAL_MPU_ConfigRegion(&MPU_InitStruct);

  /** Initializes and configures the Region and the memory to be protected
  */
  MPU_InitStruct.Number = MPU_REGION_NUMBER2;
  MPU_InitStruct.BaseAddress = 0x20000000;
  MPU_InitStruct.Size = MPU_REGION_SIZE_128KB;
  MPU_InitStruct.AccessPermission = MPU_REGION_FULL_ACCESS;
  MPU_InitStruct.IsBufferable = MPU_ACCESS_BUFFERABLE;

  HAL_MPU_ConfigRegion(&MPU_InitStruct);

  /** Initializes and configures the Region and the memory to be protected
  */
  MPU_InitStruct.Number = MPU_REGION_NUMBER3;
  MPU_InitStruct.BaseAddress = 0x24000000;
  MPU_InitStruct.Size = MPU_REGION_SIZE_512KB;
  MPU_InitStruct.SubRegionDisable = 0x07;
  MPU_InitStruct.IsBufferable = MPU_ACCESS_NOT_BUFFERABLE;

  HAL_MPU_ConfigRegion(&MPU_InitStruct);

  /** Initializes and configures the Region and the memory to be protected
  */
  MPU_InitStruct.Number = MPU_REGION_NUMBER4;
  MPU_InitStruct.BaseAddress = 0x30000000;
  MPU_InitStruct.Size = MPU_REGION_SIZE_32KB;
  MPU_InitStruct.SubRegionDisable = 0x0;
  MPU_InitStruct.IsCacheable = MPU_ACCESS_NOT_CACHEABLE;

  HAL_MPU_ConfigRegion(&MPU_InitStruct);

  /** Initializes and configures the Region and the memory to be protected
  */
  MPU_InitStruct.Number = MPU_REGION_NUMBER5;
  MPU_InitStruct.BaseAddress = 0x38000000;
  MPU_InitStruct.Size = MPU_REGION_SIZE_16KB;

  HAL_MPU_ConfigRegion(&MPU_InitStruct);

  /** Initializes and configures the Region and the memory to be protected
  */
  MPU_InitStruct.Number = MPU_REGION_NUMBER6;
  MPU_InitStruct.BaseAddress = 0x38800000;
  MPU_InitStruct.Size = MPU_REGION_SIZE_4KB;

  HAL_MPU_ConfigRegion(&MPU_InitStruct);

  /** Initializes and configures the Region and the memory to be protected
  */
  MPU_InitStruct.Number = MPU_REGION_NUMBER7;
  MPU_InitStruct.BaseAddress = 0x58000000;
  MPU_InitStruct.Size = MPU_REGION_SIZE_256KB;
  MPU_InitStruct.SubRegionDisable = 0x07;
  MPU_InitStruct.TypeExtField = MPU_TEX_LEVEL1;

  HAL_MPU_ConfigRegion(&MPU_InitStruct);

  /** Initializes and configures the Region and the memory to be protected
  */
  MPU_InitStruct.Number = MPU_REGION_NUMBER8;
  MPU_InitStruct.BaseAddress = 0x51000000;
  MPU_InitStruct.Size = MPU_REGION_SIZE_64KB;

  HAL_MPU_ConfigRegion(&MPU_InitStruct);

  /** Initializes and configures the Region and the memory to be protected
  */
  MPU_InitStruct.Number = MPU_REGION_NUMBER9;
  MPU_InitStruct.BaseAddress = 0x50000000;
  MPU_InitStruct.Size = MPU_REGION_SIZE_16KB;
  MPU_InitStruct.SubRegionDisable = 0x0;

  HAL_MPU_ConfigRegion(&MPU_InitStruct);

  /** Initializes and configures the Region and the memory to be protected
  */
  MPU_InitStruct.Number = MPU_REGION_NUMBER10;
  MPU_InitStruct.BaseAddress = 0x48020000;
  MPU_InitStruct.SubRegionDisable = 0x03;

  HAL_MPU_ConfigRegion(&MPU_InitStruct);

  /** Initializes and configures the Region and the memory to be protected
  */
  MPU_InitStruct.Number = MPU_REGION_NUMBER11;
  MPU_InitStruct.BaseAddress = 0x40020000;
  MPU_InitStruct.Size = MPU_REGION_SIZE_1MB;
  MPU_InitStruct.SubRegionDisable = 0x07;

  HAL_MPU_ConfigRegion(&MPU_InitStruct);

  /** Initializes and configures the Region and the memory to be protected
  */
  MPU_InitStruct.Number = MPU_REGION_NUMBER12;
  MPU_InitStruct.BaseAddress = 0x40010000;
  MPU_InitStruct.Size = MPU_REGION_SIZE_32KB;
  MPU_InitStruct.SubRegionDisable = 0x0;

  HAL_MPU_ConfigRegion(&MPU_InitStruct);
  /* Enables the MPU */
  HAL_MPU_Enable(MPU_PRIVILEGED_DEFAULT);

}

void HAL_TIM_PeriodElapsedCallback(TIM_HandleTypeDef *htim)
{
  if (htim->Instance == TIM17)
  {
    HAL_IncTick();
  }
}

void Error_Handler(void)
{
  __disable_irq();
  while (1)
  {
  }
}

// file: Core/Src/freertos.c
/* USER CODE BEGIN Header */
/**
  ******************************************************************************
  * File Name          : freertos.c
  * Description        : Code for freertos applications
  ******************************************************************************
  * @attention
  *
  * Copyright (c) 2025 STMicroelectronics.
  * All rights reserved.
  *
  * This software is licensed under terms that can be found in the LICENSE file
  * in the root directory of this software component.
  * If no LICENSE file comes with this software, it is provided AS-IS.
  *
  ******************************************************************************
  */
/* USER CODE END Header */

#include "FreeRTOS.h"
#include "task.h"
#include "main.h"
#include "cmsis_os.h"

osThreadId defaultTaskHandle;

void StartDefaultTask(void const * argument);

void MX_FREERTOS_Init(void); /* (MISRA C 2004 rule 8.1) */

/* GetIdleTaskMemory prototype (linked to static allocation support) */
void vApplicationGetIdleTaskMemory( StaticTask_t **ppxIdleTaskTCBBuffer, StackType_t **ppxIdleTaskStackBuffer, uint32_t *pulIdleTaskStackSize );

/* Hook prototypes */
void configureTimerForRunTimeStats(void);
unsigned long getRunTimeCounterValue(void);
void vApplicationStackOverflowHook(TaskHandle_t xTask, signed char *pcTaskName);

/* USER CODE BEGIN 1 */
/* Functions needed when configGENERATE_RUN_TIME_STATS is on */
__weak void configureTimerForRunTimeStats(void)
{

}

__weak unsigned long getRunTimeCounterValue(void)
{
return 0;
}
/* USER CODE END 1 */

/* USER CODE BEGIN 4 */
__weak void vApplicationStackOverflowHook(TaskHandle_t xTask, signed char *pcTaskName)
{
   /* Run time stack overflow checking is performed if
   configCHECK_FOR_STACK_OVERFLOW is defined to 1 or 2. This hook function is
   called if a stack overflow is detected. */
}
/* USER CODE END 4 */

/* USER CODE BEGIN GET_IDLE_TASK_MEMORY */
static StaticTask_t xIdleTaskTCBBuffer;
static StackType_t xIdleStack[configMINIMAL_STACK_SIZE];

void vApplicationGetIdleTaskMemory( StaticTask_t **ppxIdleTaskTCBBuffer, StackType_t **ppxIdleTaskStackBuffer, uint32_t *pulIdleTaskStackSize )
{
  *ppxIdleTaskTCBBuffer = &xIdleTaskTCBBuffer;
  *ppxIdleTaskStackBuffer = &xIdleStack[0];
  *pulIdleTaskStackSize = configMINIMAL_STACK_SIZE;
  /* place for user code */
}
/* USER CODE END GET_IDLE_TASK_MEMORY */

void MX_FREERTOS_Init(void) {

  /* Create the thread(s) */
  /* definition and creation of defaultTask */
  osThreadDef(defaultTask, StartDefaultTask, osPriorityNormal, 0, 1024);
  defaultTaskHandle = osThreadCreate(osThread(defaultTask), NULL);

}

__weak void StartDefaultTask(void const * argument)
{
  for(;;)
  {
    osDelay(1);
  }
}
